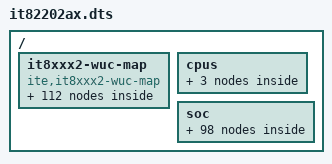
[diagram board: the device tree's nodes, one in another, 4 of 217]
/dts-v1/;

/ {
	#address-cells = < 0x1 >;
	#size-cells = < 0x1 >;
	it8xxx2-wuc-map {
		compatible = "ite,it8xxx2-wuc-map";
		wuc_wu20: wu20 {
			wucs = < &wuc2 0x1 >;
		};
		wuc_wu21: wu21 {
			wucs = < &wuc2 0x2 >;
		};
		wuc_wu22: wu22 {
			wucs = < &wuc2 0x4 >;
		};
		wuc_wu23: wu23 {
			wucs = < &wuc2 0x8 >;
		};
		wuc_wu24: wu24 {
			wucs = < &wuc2 0x10 >;
		};
		wuc_wu25: wu25 {
			wucs = < &wuc2 0x20 >;
		};
		wuc_wu30: wu30 {
			wucs = < &wuc3 0x1 >;
			phandle = < 0x18 >;
		};
		wuc_wu31: wu31 {
			wucs = < &wuc3 0x2 >;
			phandle = < 0x19 >;
		};
		wuc_wu32: wu32 {
			wucs = < &wuc3 0x4 >;
			phandle = < 0x1a >;
		};
		wuc_wu33: wu33 {
			wucs = < &wuc3 0x8 >;
			phandle = < 0x1b >;
		};
		wuc_wu34: wu34 {
			wucs = < &wuc3 0x10 >;
			phandle = < 0x1c >;
		};
		wuc_wu35: wu35 {
			wucs = < &wuc3 0x20 >;
			phandle = < 0x1d >;
		};
		wuc_wu36: wu36 {
			wucs = < &wuc3 0x40 >;
			phandle = < 0x1e >;
		};
		wuc_wu37: wu37 {
			wucs = < &wuc3 0x80 >;
			phandle = < 0x1f >;
		};
		wuc_wu40: wu40 {
			wucs = < &wuc4 0x1 >;
		};
		wuc_wu42: wu42 {
			wucs = < &wuc4 0x4 >;
			phandle = < 0x16 >;
		};
		wuc_wu45: wu45 {
			wucs = < &wuc4 0x20 >;
		};
		wuc_wu46: wu46 {
			wucs = < &wuc4 0x40 >;
		};
		wuc_wu50: wu50 {
			wucs = < &wuc5 0x1 >;
		};
		wuc_wu51: wu51 {
			wucs = < &wuc5 0x2 >;
		};
		wuc_wu52: wu52 {
			wucs = < &wuc5 0x4 >;
		};
		wuc_wu53: wu53 {
			wucs = < &wuc5 0x8 >;
		};
		wuc_wu54: wu54 {
			wucs = < &wuc5 0x10 >;
		};
		wuc_wu55: wu55 {
			wucs = < &wuc5 0x20 >;
		};
		wuc_wu56: wu56 {
			wucs = < &wuc5 0x40 >;
		};
		wuc_wu57: wu57 {
			wucs = < &wuc5 0x80 >;
		};
		wuc_wu60: wu60 {
			wucs = < &wuc6 0x1 >;
		};
		wuc_wu61: wu61 {
			wucs = < &wuc6 0x2 >;
		};
		wuc_wu62: wu62 {
			wucs = < &wuc6 0x4 >;
		};
		wuc_wu63: wu63 {
			wucs = < &wuc6 0x8 >;
		};
		wuc_wu64: wu64 {
			wucs = < &wuc6 0x10 >;
		};
		wuc_wu65: wu65 {
			wucs = < &wuc6 0x20 >;
		};
		wuc_wu66: wu66 {
			wucs = < &wuc6 0x40 >;
		};
		wuc_wu67: wu67 {
			wucs = < &wuc6 0x80 >;
		};
		wuc_wu70: wu70 {
			wucs = < &wuc7 0x1 >;
		};
		wuc_wu71: wu71 {
			wucs = < &wuc7 0x2 >;
		};
		wuc_wu72: wu72 {
			wucs = < &wuc7 0x4 >;
		};
		wuc_wu73: wu73 {
			wucs = < &wuc7 0x8 >;
		};
		wuc_wu74: wu74 {
			wucs = < &wuc7 0x10 >;
		};
		wuc_wu75: wu75 {
			wucs = < &wuc7 0x20 >;
		};
		wuc_wu76: wu76 {
			wucs = < &wuc7 0x40 >;
		};
		wuc_wu77: wu77 {
			wucs = < &wuc7 0x80 >;
		};
		wuc_wu80: wu80 {
			wucs = < &wuc8 0x1 >;
		};
		wuc_wu81: wu81 {
			wucs = < &wuc8 0x2 >;
		};
		wuc_wu82: wu82 {
			wucs = < &wuc8 0x4 >;
		};
		wuc_wu83: wu83 {
			wucs = < &wuc8 0x8 >;
		};
		wuc_wu84: wu84 {
			wucs = < &wuc8 0x10 >;
		};
		wuc_wu85: wu85 {
			wucs = < &wuc8 0x20 >;
		};
		wuc_wu86: wu86 {
			wucs = < &wuc8 0x40 >;
		};
		wuc_wu87: wu87 {
			wucs = < &wuc8 0x80 >;
		};
		wuc_wu88: wu88 {
			wucs = < &wuc9 0x1 >;
		};
		wuc_wu89: wu89 {
			wucs = < &wuc9 0x2 >;
		};
		wuc_wu90: wu90 {
			wucs = < &wuc9 0x4 >;
			phandle = < 0x24 >;
		};
		wuc_wu91: wu91 {
			wucs = < &wuc9 0x8 >;
		};
		wuc_wu92: wu92 {
			wucs = < &wuc9 0x10 >;
		};
		wuc_wu93: wu93 {
			wucs = < &wuc9 0x20 >;
		};
		wuc_wu94: wu94 {
			wucs = < &wuc9 0x40 >;
		};
		wuc_wu95: wu95 {
			wucs = < &wuc9 0x80 >;
		};
		wuc_wu96: wu96 {
			wucs = < &wuc10 0x1 >;
		};
		wuc_wu97: wu97 {
			wucs = < &wuc10 0x2 >;
		};
		wuc_wu98: wu98 {
			wucs = < &wuc10 0x4 >;
		};
		wuc_wu99: wu99 {
			wucs = < &wuc10 0x8 >;
		};
		wuc_wu100: wu100 {
			wucs = < &wuc10 0x10 >;
		};
		wuc_wu101: wu101 {
			wucs = < &wuc10 0x20 >;
		};
		wuc_wu102: wu102 {
			wucs = < &wuc10 0x40 >;
		};
		wuc_wu103: wu103 {
			wucs = < &wuc10 0x80 >;
		};
		wuc_wu104: wu104 {
			wucs = < &wuc11 0x1 >;
		};
		wuc_wu105: wu105 {
			wucs = < &wuc11 0x2 >;
		};
		wuc_wu106: wu106 {
			wucs = < &wuc11 0x4 >;
		};
		wuc_wu107: wu107 {
			wucs = < &wuc11 0x8 >;
		};
		wuc_wu108: wu108 {
			wucs = < &wuc11 0x10 >;
		};
		wuc_wu109: wu109 {
			wucs = < &wuc11 0x20 >;
		};
		wuc_wu110: wu110 {
			wucs = < &wuc11 0x40 >;
		};
		wuc_wu111: wu111 {
			wucs = < &wuc11 0x80 >;
		};
		wuc_wu112: wu112 {
			wucs = < &wuc12 0x1 >;
		};
		wuc_wu113: wu113 {
			wucs = < &wuc12 0x2 >;
		};
		wuc_wu114: wu114 {
			wucs = < &wuc12 0x4 >;
		};
		wuc_wu115: wu115 {
			wucs = < &wuc12 0x8 >;
		};
		wuc_wu116: wu116 {
			wucs = < &wuc12 0x10 >;
		};
		wuc_wu117: wu117 {
			wucs = < &wuc12 0x20 >;
		};
		wuc_wu118: wu118 {
			wucs = < &wuc12 0x40 >;
		};
		wuc_wu119: wu119 {
			wucs = < &wuc12 0x80 >;
		};
		wuc_wu120: wu120 {
			wucs = < &wuc13 0x1 >;
		};
		wuc_wu121: wu121 {
			wucs = < &wuc13 0x2 >;
		};
		wuc_wu122: wu122 {
			wucs = < &wuc13 0x4 >;
		};
		wuc_wu123: wu123 {
			wucs = < &wuc13 0x8 >;
		};
		wuc_wu124: wu124 {
			wucs = < &wuc13 0x10 >;
		};
		wuc_wu125: wu125 {
			wucs = < &wuc13 0x20 >;
		};
		wuc_wu126: wu126 {
			wucs = < &wuc13 0x40 >;
		};
		wuc_wu128: wu128 {
			wucs = < &wuc14 0x1 >;
		};
		wuc_wu129: wu129 {
			wucs = < &wuc14 0x2 >;
		};
		wuc_wu130: wu130 {
			wucs = < &wuc14 0x4 >;
		};
		wuc_wu131: wu131 {
			wucs = < &wuc14 0x8 >;
		};
		wuc_wu132: wu132 {
			wucs = < &wuc14 0x10 >;
		};
		wuc_wu133: wu133 {
			wucs = < &wuc14 0x20 >;
		};
		wuc_wu134: wu134 {
			wucs = < &wuc14 0x40 >;
		};
		wuc_wu135: wu135 {
			wucs = < &wuc14 0x80 >;
		};
		wuc_wu136: wu136 {
			wucs = < &wuc15 0x1 >;
		};
		wuc_wu137: wu137 {
			wucs = < &wuc15 0x2 >;
		};
		wuc_wu138: wu138 {
			wucs = < &wuc15 0x4 >;
		};
		wuc_wu139: wu139 {
			wucs = < &wuc15 0x8 >;
		};
		wuc_wu140: wu140 {
			wucs = < &wuc15 0x10 >;
		};
		wuc_wu141: wu141 {
			wucs = < &wuc15 0x20 >;
		};
		wuc_wu142: wu142 {
			wucs = < &wuc15 0x40 >;
		};
		wuc_wu143: wu143 {
			wucs = < &wuc15 0x80 >;
		};
		wuc_wu144: wu144 {
			wucs = < &wuc16 0x1 >;
		};
		wuc_wu145: wu145 {
			wucs = < &wuc16 0x2 >;
		};
		wuc_wu146: wu146 {
			wucs = < &wuc16 0x4 >;
		};
		wuc_wu147: wu147 {
			wucs = < &wuc16 0x8 >;
		};
		wuc_wu148: wu148 {
			wucs = < &wuc16 0x10 >;
		};
		wuc_wu149: wu149 {
			wucs = < &wuc16 0x20 >;
		};
		wuc_wu150: wu150 {
			wucs = < &wuc16 0x40 >;
		};
	};
	cpus {
		#address-cells = < 0x1 >;
		#size-cells = < 0x0 >;
		cpu0: cpu@0 {
			compatible = "ite,riscv-ite", "riscv";
			riscv,isa = "rv32imafc_zifencei";
			device_type = "cpu";
			reg = < 0x0 >;
			cpu-power-states = < &standby >;
		};
		power-states {
			standby: standby {
				compatible = "zephyr,power-state";
				power-state-name = "standby";
				min-residency-us = < 0x1f4 >;
				phandle = < 0x10 >;
			};
		};
	};
	soc {
		#address-cells = < 0x1 >;
		#size-cells = < 0x1 >;
		ranges;
		bbram: bb-ram@f02200 {
			#address-cells = < 0x1 >;
			#size-cells = < 0x1 >;
			compatible = "ite,it8xxx2-bbram";
			status = "okay";
			reg = < 0xf02200 0xc0 >;
		};
		flashctrl: flash-controller@f01000 {
			compatible = "ite,it8xxx2-flash-controller";
			reg = < 0xf01000 0x100 >;
			#address-cells = < 0x1 >;
			#size-cells = < 0x1 >;
			flash0: flash@80000000 {
				compatible = "soc-nv-flash";
				reg = < 0x80000000 0x100000 >;
				erase-block-size = < 0x1000 >;
				write-block-size = < 0x4 >;
			};
		};
		sram0: memory@80100000 {
			compatible = "mmio-sram";
			reg = < 0x80100000 0x40000 >;
		};
		ilm: ilm@f01040 {
			compatible = "ite,it8xxx2-ilm";
			reg = < 0xf01040 0x3 0xf01043 0x3 0xf01046 0x3 0xf01049 0x3 0xf0104c 0x3 0xf01081 0x3 0xf01084 0x3 0xf01087 0x3 0xf0108a 0x3 0xf0108d 0x3 0xf01090 0x3 0xf01093 0x3 0xf01096 0x3 0xf010b0 0x3 0xf010b3 0x3 0xf010b6 0x3 0xf010b9 0x3 0xf010bc 0x3 0xf010bf 0x3 0xf010c2 0x3 0xf010c5 0x3 0xf010c8 0x3 0xf010cb 0x3 0xf010ce 0x3 >;
		};
		uart1: uart@f02700 {
			compatible = "ns16550";
			reg = < 0xf02700 0x20 >;
			status = "disabled";
			current-speed = < 0x1c200 >;
			clock-frequency = < 0x1c2000 >;
			interrupts = < 0x26 0x1 >;
			interrupt-parent = < &intc >;
			reg-shift = < 0x0 >;
			phandle = < 0x13 >;
		};
		uart2: uart@f02800 {
			compatible = "ns16550";
			reg = < 0xf02800 0x20 >;
			status = "disabled";
			current-speed = < 0x70800 >;
			clock-frequency = < 0x1c2000 >;
			interrupts = < 0x27 0x1 >;
			interrupt-parent = < &intc >;
			reg-shift = < 0x0 >;
			phandle = < 0x15 >;
		};
		ite_uart1_wrapper: uartwrapper@f02720 {
			compatible = "ite,it8xxx2-uart";
			reg = < 0xf02720 0x20 >;
			status = "disabled";
			port-num = < 0x1 >;
			gpios = < &gpiob 0x0 0x0 >;
			uart-dev = < &uart1 >;
		};
		ite_uart2_wrapper: uartwrapper@f02820 {
			compatible = "ite,it8xxx2-uart";
			reg = < 0xf02820 0x20 >;
			status = "disabled";
			port-num = < 0x2 >;
			gpios = < &gpiof 0x0 0x0 >;
			uart-dev = < &uart2 >;
		};
		timer: timer@f01f10 {
			compatible = "ite,it8xxx2-timer";
			reg = < 0xf01f10 0x52 >;
			interrupts = < 0x9b 0x1 0x9c 0x1 0x9d 0x1 0x9e 0x1 0x9f 0x1 0x50 0x1 >;
			interrupt-parent = < &intc >;
		};
		gpioa: gpio@f01601 {
			compatible = "ite,it8xxx2-gpio-v2";
			reg = < 0xf01601 0x1 0xf01618 0x1 0xf01630 0x1 0xf01648 0x1 0xf01660 0x8 >;
			ngpios = < 0x8 >;
			gpio-controller;
			interrupts = < 0x60 0x4 0x61 0x4 0x62 0x4 0x58 0x4 0x59 0x4 0x5a 0x4 0x5b 0x4 0x69 0x4 >;
			interrupt-parent = < &intc >;
			#gpio-cells = < 0x2 >;
			wuc-base = < 0xf01b20 0xf01b20 0xf01b20 0xf01b1c 0xf01b1c 0xf01b1c 0xf01b1c 0xf01b24 >;
			wuc-mask = < 0x8 0x10 0x20 0x1 0x2 0x4 0x8 0x10 >;
			has-volt-sel = < 0x1 0x1 0x1 0x1 0x1 0x1 0x1 0x1 >;
			phandle = < 0x23 >;
		};
		gpiob: gpio@f01602 {
			compatible = "ite,it8xxx2-gpio-v2";
			reg = < 0xf01602 0x1 0xf01619 0x1 0xf01631 0x1 0xf01649 0x1 0xf01668 0x8 >;
			ngpios = < 0x7 >;
			gpio-controller;
			interrupts = < 0x6a 0x4 0x6b 0x4 0x5c 0x4 0x6c 0x4 0x63 0x4 0x6d 0x4 0x6e 0x4 0x0 0x0 >;
			interrupt-parent = < &intc >;
			wakeup-source;
			#gpio-cells = < 0x2 >;
			wuc-base = < 0xf01b24 0xf01b24 0xf01b1c 0xf01b24 0xf01b20 0xf01b28 0xf01b28 0x0 >;
			wuc-mask = < 0x20 0x40 0x10 0x80 0x40 0x1 0x2 0x0 >;
			has-volt-sel = < 0x1 0x1 0x1 0x1 0x1 0x1 0x1 0x0 >;
			phandle = < 0x12 >;
		};
		gpioc: gpio@f01603 {
			compatible = "ite,it8xxx2-gpio-v2";
			reg = < 0xf01603 0x1 0xf0161a 0x1 0xf01632 0x1 0xf0164a 0x1 0xf01670 0x8 >;
			ngpios = < 0x8 >;
			gpio-controller;
			interrupts = < 0x5d 0x4 0x70 0x4 0x64 0x4 0x71 0x4 0x15 0x4 0x72 0x4 0x6 0x4 0x5e 0x4 >;
			interrupt-parent = < &intc >;
			#gpio-cells = < 0x2 >;
			wuc-base = < 0xf01b1c 0xf01b28 0xf01b20 0xf01b28 0xf01b04 0xf01b28 0xf01b04 0xf01b1c >;
			wuc-mask = < 0x20 0x8 0x80 0x10 0x4 0x20 0x8 0x40 >;
			has-volt-sel = < 0x1 0x1 0x1 0x1 0x1 0x1 0x1 0x1 >;
			phandle = < 0x20 >;
		};
		gpiod: gpio@f01604 {
			compatible = "ite,it8xxx2-gpio-v2";
			reg = < 0xf01604 0x1 0xf0161b 0x1 0xf01633 0x1 0xf0164b 0x1 0xf01678 0x8 >;
			ngpios = < 0x8 >;
			gpio-controller;
			interrupts = < 0x1 0x4 0x1f 0x4 0x11 0x4 0x73 0x4 0x74 0x4 0x75 0x4 0x76 0x4 0x5f 0x4 >;
			interrupt-parent = < &intc >;
			#gpio-cells = < 0x2 >;
			wuc-base = < 0xf01b04 0xf01b04 0xf01b04 0xf01b28 0xf01b28 0xf01b2c 0xf01b2c 0xf01b1c >;
			wuc-mask = < 0x1 0x2 0x10 0x40 0x80 0x1 0x2 0x80 >;
			has-volt-sel = < 0x1 0x1 0x1 0x1 0x1 0x1 0x1 0x1 >;
		};
		gpioe: gpio@f01605 {
			compatible = "ite,it8xxx2-gpio-v2";
			reg = < 0xf01605 0x1 0xf0161c 0x1 0xf01634 0x1 0xf0164c 0x1 0xf01680 0x8 >;
			ngpios = < 0x8 >;
			gpio-controller;
			interrupts = < 0x48 0x4 0x49 0x4 0x4a 0x4 0x4b 0x4 0x77 0x4 0xb0 0x4 0xb1 0x4 0xb2 0x4 >;
			interrupt-parent = < &intc >;
			#gpio-cells = < 0x2 >;
			wuc-base = < 0xf01b18 0xf01b18 0xf01b18 0xf01b18 0xf01b2c 0xf01b0c 0xf01b0c 0xf01b0c >;
			wuc-mask = < 0x1 0x2 0x4 0x8 0x4 0x1 0x20 0x40 >;
			has-volt-sel = < 0x1 0x1 0x1 0x1 0x1 0x1 0x1 0x1 >;
			phandle = < 0x22 >;
		};
		gpiof: gpio@f01606 {
			compatible = "ite,it8xxx2-gpio-v2";
			reg = < 0xf01606 0x1 0xf0161d 0x1 0xf01635 0x1 0xf0164d 0x1 0xf01688 0x8 >;
			ngpios = < 0x8 >;
			gpio-controller;
			interrupts = < 0x65 0x4 0x66 0x4 0x67 0x4 0x68 0x4 0x34 0x4 0x35 0x4 0x36 0x4 0x37 0x4 >;
			interrupt-parent = < &intc >;
			#gpio-cells = < 0x2 >;
			wuc-base = < 0xf01b24 0xf01b24 0xf01b24 0xf01b24 0xf01b14 0xf01b14 0xf01b14 0xf01b14 >;
			wuc-mask = < 0x1 0x2 0x4 0x8 0x10 0x20 0x40 0x80 >;
			has-volt-sel = < 0x1 0x1 0x1 0x1 0x1 0x1 0x1 0x1 >;
			phandle = < 0x14 >;
		};
		gpiog: gpio@f01607 {
			compatible = "ite,it8xxx2-gpio-v2";
			reg = < 0xf01607 0x1 0xf0161e 0x1 0xf01636 0x1 0xf0164e 0x1 0xf01690 0x8 >;
			ngpios = < 0x8 >;
			gpio-controller;
			interrupts = < 0x78 0x4 0x79 0x4 0x7a 0x4 0x90 0x4 0x91 0x4 0x92 0x4 0x7b 0x4 0x93 0x4 >;
			interrupt-parent = < &intc >;
			#gpio-cells = < 0x2 >;
			wuc-base = < 0xf01b2c 0xf01b2c 0xf01b2c 0xf01b30 0xf01b30 0xf01b30 0xf01b2c 0xf01b30 >;
			wuc-mask = < 0x8 0x10 0x20 0x8 0x10 0x20 0x40 0x40 >;
			has-volt-sel = < 0x1 0x1 0x1 0x0 0x0 0x0 0x1 0x0 >;
		};
		gpioh: gpio@f01608 {
			compatible = "ite,it8xxx2-gpio-v2";
			reg = < 0xf01608 0x1 0xf0161f 0x1 0xf01637 0x1 0xf0164f 0x1 0xf01698 0x8 >;
			ngpios = < 0x7 >;
			gpio-controller;
			interrupts = < 0x30 0x4 0x31 0x4 0x32 0x4 0x33 0x4 0x55 0x4 0x56 0x4 0x57 0x4 0x0 0x0 >;
			interrupt-parent = < &intc >;
			wakeup-source;
			#gpio-cells = < 0x2 >;
			wuc-base = < 0xf01b14 0xf01b14 0xf01b14 0xf01b14 0xf01b20 0xf01b20 0xf01b20 0x0 >;
			wuc-mask = < 0x1 0x2 0x4 0x8 0x1 0x2 0x4 0x0 >;
			has-volt-sel = < 0x1 0x1 0x1 0x1 0x1 0x1 0x1 0x0 >;
			phandle = < 0x21 >;
		};
		gpioi: gpio@f01609 {
			compatible = "ite,it8xxx2-gpio-v2";
			reg = < 0xf01609 0x1 0xf01620 0x1 0xf01638 0x1 0xf01650 0x1 0xf016a0 0x8 >;
			ngpios = < 0x8 >;
			gpio-controller;
			interrupts = < 0x7c 0x4 0x7d 0x4 0x7e 0x4 0x7f 0x4 0x4c 0x4 0x4d 0x4 0x4e 0x4 0x4f 0x4 >;
			interrupt-parent = < &intc >;
			#gpio-cells = < 0x2 >;
			wuc-base = < 0xf01b2c 0xf01b30 0xf01b30 0xf01b30 0xf01b18 0xf01b18 0xf01b18 0xf01b18 >;
			wuc-mask = < 0x80 0x1 0x2 0x4 0x10 0x20 0x40 0x80 >;
			has-volt-sel = < 0x1 0x1 0x1 0x1 0x1 0x1 0x1 0x1 >;
		};
		gpioj: gpio@f0160a {
			compatible = "ite,it8xxx2-gpio-v2";
			reg = < 0xf0160a 0x1 0xf01621 0x1 0xf01639 0x1 0xf01651 0x1 0xf016a8 0x8 >;
			ngpios = < 0x8 >;
			gpio-controller;
			interrupts = < 0x80 0x4 0x81 0x4 0x82 0x4 0x83 0x4 0x84 0x4 0x85 0x4 0x86 0x4 0x87 0x4 >;
			interrupt-parent = < &intc >;
			#gpio-cells = < 0x2 >;
			wuc-base = < 0xf01b34 0xf01b34 0xf01b34 0xf01b34 0xf01b34 0xf01b34 0xf01b34 0xf01b34 >;
			wuc-mask = < 0x1 0x2 0x4 0x8 0x10 0x20 0x40 0x80 >;
			has-volt-sel = < 0x1 0x1 0x1 0x1 0x1 0x1 0x1 0x1 >;
		};
		gpiok: gpio@f0160b {
			compatible = "ite,it8xxx2-gpio-v2";
			reg = < 0xf0160b 0x1 0xf01622 0x1 0xf0163a 0x1 0xf01652 0x1 0xf016b0 0x8 >;
			ngpios = < 0x8 >;
			gpio-controller;
			interrupts = < 0x28 0x4 0x29 0x4 0x2a 0x4 0x2b 0x4 0x2c 0x4 0x2d 0x4 0x2e 0x4 0x2f 0x4 >;
			interrupt-parent = < &intc >;
			#gpio-cells = < 0x2 >;
			wuc-base = < 0xf01b10 0xf01b10 0xf01b10 0xf01b10 0xf01b10 0xf01b10 0xf01b10 0xf01b10 >;
			wuc-mask = < 0x1 0x2 0x4 0x8 0x10 0x20 0x40 0x80 >;
			has-volt-sel = < 0x1 0x1 0x1 0x1 0x1 0x1 0x1 0x1 >;
		};
		gpiol: gpio@f0160c {
			compatible = "ite,it8xxx2-gpio-v2";
			reg = < 0xf0160c 0x1 0xf01623 0x1 0xf0163b 0x1 0xf01653 0x1 0xf016b8 0x8 >;
			ngpios = < 0x8 >;
			gpio-controller;
			interrupts = < 0x88 0x4 0x89 0x4 0x8a 0x4 0x8b 0x4 0x8c 0x4 0x8d 0x4 0x8e 0x4 0x8f 0x4 >;
			interrupt-parent = < &intc >;
			#gpio-cells = < 0x2 >;
			wuc-base = < 0xf01b38 0xf01b38 0xf01b38 0xf01b38 0xf01b38 0xf01b38 0xf01b38 0xf01b38 >;
			wuc-mask = < 0x1 0x2 0x4 0x8 0x10 0x20 0x40 0x80 >;
			has-volt-sel = < 0x1 0x1 0x1 0x1 0x1 0x1 0x1 0x1 >;
		};
		gpiom: gpio@f0160d {
			compatible = "ite,it8xxx2-gpio-v2";
			reg = < 0xf0160d 0x1 0xf01624 0x1 0xf0163c 0x1 0xf01654 0x1 0xf016c0 0x8 >;
			ngpios = < 0x7 >;
			gpio-controller;
			interrupts = < 0xb3 0x4 0xb4 0x4 0xb5 0x4 0xb6 0x4 0xb7 0x4 0xb8 0x4 0xb9 0x4 0x0 0x0 >;
			interrupt-parent = < &intc >;
			#gpio-cells = < 0x2 >;
			wuc-base = < 0xf01b3c 0xf01b3c 0xf01b3c 0xf01b3c 0xf01b3c 0xf01b3c 0xf01b3c 0x0 >;
			wuc-mask = < 0x1 0x2 0x4 0x8 0x10 0x20 0x40 0x0 >;
			has-volt-sel = < 0x1 0x1 0x1 0x1 0x1 0x1 0x1 0x0 >;
		};
		espi0: espi@f03100 {
			compatible = "ite,it8xxx2-espi";
			reg = < 0xf03100 0xd8 0xf03200 0x9a 0xf03300 0xd0 0xf03400 0xc0 0xf01200 0x6 0xf01300 0xb 0xf01500 0x100 0xf01000 0xd1 >;
			interrupts = < 0xa2 0x4 0xa3 0x4 0x18 0x4 0x2 0x4 0x19 0x4 0xa4 0x4 0x1b 0x4 0x5 0x4 >;
			interrupt-parent = < &intc >;
			wucctrl = < &wuc_wu42 >;
			#address-cells = < 0x1 >;
			#size-cells = < 0x1 >;
			status = "disabled";
		};
		spi0: spi@f02600 {
			#address-cells = < 0x1 >;
			#size-cells = < 0x0 >;
			compatible = "ite,it8xxx2-sspi";
			reg = < 0xf02600 0x40 >;
			interrupt-parent = < &intc >;
			interrupts = < 0x25 0x1 >;
			clock-frequency = < 0x1c200 >;
		};
		spi1: spi@f02640 {
			#address-cells = < 0x1 >;
			#size-cells = < 0x0 >;
			compatible = "ite,it8xxx2-sspi";
			reg = < 0xf02640 0x40 >;
			interrupts = < 0x25 0x1 >;
			interrupt-parent = < &intc >;
			status = "okay";
		};
		shi0: shi@f03a00 {
			compatible = "ite,it8xxx2-shi";
			reg = < 0xf03a00 0x30 >;
			interrupts = < 0xab 0x0 >;
			interrupt-parent = < &intc >;
			status = "disabled";
			buffer-rx-size = < 0x100 >;
			buffer-tx-size = < 0x100 >;
		};
		adc0: adc@f01900 {
			compatible = "ite,it8xxx2-adc";
			reg = < 0xf01900 0x45 >;
			interrupts = < 0x8 0x0 >;
			interrupt-parent = < &intc >;
			status = "disabled";
			#io-channel-cells = < 0x1 >;
		};
		vcmp0: vcmp@f01946 {
			compatible = "ite,it8xxx2-vcmp";
			reg = < 0xf01946 0x1 0xf01977 0x1 0xf01937 0x1 0xf01947 0x1 0xf01948 0x1 0xf01945 0x1 0xf0196d 0x1 >;
			interrupts = < 0x97 0x4 >;
			interrupt-parent = < &intc >;
			vcmp-ch = < 0x0 >;
			status = "disabled";
		};
		vcmp1: vcmp@f01949 {
			compatible = "ite,it8xxx2-vcmp";
			reg = < 0xf01949 0x1 0xf01978 0x1 0xf01937 0x1 0xf0194a 0x1 0xf0194b 0x1 0xf01945 0x1 0xf0196d 0x1 >;
			interrupts = < 0x97 0x4 >;
			interrupt-parent = < &intc >;
			vcmp-ch = < 0x1 >;
			status = "disabled";
		};
		vcmp2: vcmp@f0194c {
			compatible = "ite,it8xxx2-vcmp";
			reg = < 0xf0194c 0x1 0xf01979 0x1 0xf01937 0x1 0xf0194d 0x1 0xf0194e 0x1 0xf01945 0x1 0xf0196d 0x1 >;
			interrupts = < 0x97 0x4 >;
			interrupt-parent = < &intc >;
			vcmp-ch = < 0x2 >;
			status = "disabled";
		};
		vcmp3: vcmp@f0196e {
			compatible = "ite,it8xxx2-vcmp";
			reg = < 0xf0196e 0x1 0xf0197a 0x1 0xf01937 0x1 0xf0196f 0x1 0xf01970 0x1 0xf01945 0x1 0xf0196d 0x1 >;
			interrupts = < 0x97 0x4 >;
			interrupt-parent = < &intc >;
			vcmp-ch = < 0x3 >;
			status = "disabled";
		};
		vcmp4: vcmp@f01971 {
			compatible = "ite,it8xxx2-vcmp";
			reg = < 0xf01971 0x1 0xf0197b 0x1 0xf01937 0x1 0xf01972 0x1 0xf01973 0x1 0xf01945 0x1 0xf0196d 0x1 >;
			interrupts = < 0x97 0x4 >;
			interrupt-parent = < &intc >;
			vcmp-ch = < 0x4 >;
			status = "disabled";
		};
		vcmp5: vcmp@f01974 {
			compatible = "ite,it8xxx2-vcmp";
			reg = < 0xf01974 0x1 0xf0197c 0x1 0xf01937 0x1 0xf01975 0x1 0xf01976 0x1 0xf01945 0x1 0xf0196d 0x1 >;
			interrupts = < 0x97 0x4 >;
			interrupt-parent = < &intc >;
			vcmp-ch = < 0x5 >;
			status = "disabled";
		};
		ecpm: clock-controller@f01e00 {
			compatible = "ite,it8xxx2-ecpm";
			reg = < 0xf01e00 0x11 >;
			reg-names = "ecpm";
		};
		prs: pwmprs@f01800 {
			compatible = "ite,it8xxx2-pwmprs";
			reg = < 0xf01800 0x1 >;
			phandle = < 0x17 >;
		};
		pwm0: pwm@f01802 {
			compatible = "ite,it8xxx2-pwm";
			reg = < 0xf01802 0x1 0xf0180c 0x1 0xf0180f 0x1 0xf0180a 0x1 >;
			channel = < 0x0 >;
			status = "disabled";
			pwmctrl = < &prs >;
			#pwm-cells = < 0x3 >;
		};
		pwm1: pwm@f01803 {
			compatible = "ite,it8xxx2-pwm";
			reg = < 0xf01803 0x1 0xf0180c 0x1 0xf0180f 0x1 0xf0180a 0x1 >;
			channel = < 0x1 >;
			status = "disabled";
			pwmctrl = < &prs >;
			#pwm-cells = < 0x3 >;
		};
		pwm2: pwm@f01804 {
			compatible = "ite,it8xxx2-pwm";
			reg = < 0xf01804 0x1 0xf0180c 0x1 0xf0180f 0x1 0xf0180a 0x1 >;
			channel = < 0x2 >;
			status = "disabled";
			pwmctrl = < &prs >;
			#pwm-cells = < 0x3 >;
		};
		pwm3: pwm@f01805 {
			compatible = "ite,it8xxx2-pwm";
			reg = < 0xf01805 0x1 0xf0180c 0x1 0xf0180f 0x1 0xf0180a 0x1 >;
			channel = < 0x3 >;
			status = "disabled";
			pwmctrl = < &prs >;
			#pwm-cells = < 0x3 >;
		};
		pwm4: pwm@f01806 {
			compatible = "ite,it8xxx2-pwm";
			reg = < 0xf01806 0x1 0xf0180d 0x1 0xf0180f 0x1 0xf0180a 0x1 >;
			channel = < 0x4 >;
			status = "disabled";
			pwmctrl = < &prs >;
			#pwm-cells = < 0x3 >;
		};
		pwm5: pwm@f01807 {
			compatible = "ite,it8xxx2-pwm";
			reg = < 0xf01807 0x1 0xf0180d 0x1 0xf0180f 0x1 0xf0180a 0x1 >;
			channel = < 0x5 >;
			status = "disabled";
			pwmctrl = < &prs >;
			#pwm-cells = < 0x3 >;
		};
		pwm6: pwm@f01808 {
			compatible = "ite,it8xxx2-pwm";
			reg = < 0xf01808 0x1 0xf0180d 0x1 0xf0180f 0x1 0xf0180a 0x1 >;
			channel = < 0x6 >;
			status = "disabled";
			pwmctrl = < &prs >;
			#pwm-cells = < 0x3 >;
		};
		pwm7: pwm@f01809 {
			compatible = "ite,it8xxx2-pwm";
			reg = < 0xf01809 0x1 0xf0180d 0x1 0xf0180f 0x1 0xf0180a 0x1 >;
			channel = < 0x7 >;
			status = "disabled";
			pwmctrl = < &prs >;
			#pwm-cells = < 0x3 >;
		};
		tach0: tach@f0181e {
			compatible = "ite,it8xxx2-tach";
			reg = < 0xf0181e 0x1 0xf0181f 0x1 0xf01848 0x1 >;
			dvs-bit = < 0x8 >;
			chsel-bit = < 0x4 >;
			status = "disabled";
		};
		tach1: tach@f01820 {
			compatible = "ite,it8xxx2-tach";
			reg = < 0xf01820 0x1 0xf01821 0x1 0xf01848 0x1 >;
			dvs-bit = < 0x2 >;
			chsel-bit = < 0x1 >;
			status = "disabled";
		};
		gctrl: general-control@f02000 {
			compatible = "ite,it8xxx2-gctrl";
			reg = < 0xf02000 0x100 >;
		};
		peci0: peci@f02c00 {
			compatible = "ite,it8xxx2-peci";
			reg = < 0xf02c00 0xf >;
			#address-cells = < 0x1 >;
			#size-cells = < 0x0 >;
			interrupt-parent = < &intc >;
			interrupts = < 0xa0 0x4 >;
			status = "disabled";
		};
		kbd: kbd@f01d00 {
			compatible = "ite,it8xxx2-kbd";
			reg = < 0xf01d00 0x29 >;
			interrupt-parent = < &intc >;
			interrupts = < 0xd 0x4 >;
			status = "disabled";
			wucctrl = < &wuc_wu30 &wuc_wu31 &wuc_wu32 &wuc_wu33 &wuc_wu34 &wuc_wu35 &wuc_wu36 &wuc_wu37 >;
			kso16-gpios = < &gpioc 0x3 0x16 >;
			kso17-gpios = < &gpioc 0x5 0x16 >;
		};
		usbpd0: usbpd@f03700 {
			compatible = "ite,it8xxx2-usbpd";
			reg = < 0xf03700 0x100 >;
			status = "disabled";
		};
		usbpd1: usbpd@f03800 {
			compatible = "ite,it8xxx2-usbpd";
			reg = < 0xf03800 0x100 >;
			status = "disabled";
		};
		intc: interrupt-controller@f03f00 {
			compatible = "ite,it8xxx2-intc-v2";
			#address-cells = < 0x0 >;
			#interrupt-cells = < 0x2 >;
			interrupt-controller;
			reg = < 0xf03f00 0x100 >;
			phandle = < 0x11 >;
		};
		twd0: watchdog@f01f80 {
			compatible = "ite,it8xxx2-watchdog";
			reg = < 0xf01f80 0xf >;
			interrupts = < 0x1e 0x1 0x3a 0x1 >;
			interrupt-parent = < &intc >;
		};
		gpiogcr: gpio-gcr@f03e00 {
			compatible = "ite,it8xxx2-gpiogcr";
			reg = < 0xf03e00 0x2f >;
		};
		gpioksi: gpio@f01d08 {
			compatible = "ite,it8xxx2-gpio-v2";
			reg = < 0xf01d08 0x1 0xf01d09 0x1 0xf01d2c 0x1 0x0 0x1 0xf01d40 0x8 >;
			ngpios = < 0x8 >;
			gpio-controller;
			interrupts = < 0x0 0x0 0x0 0x0 0x0 0x0 0x0 0x0 0x0 0x0 0x0 0x0 0x0 0x0 0x0 0x0 >;
			interrupt-parent = < &intc >;
			keyboard-controller;
			#gpio-cells = < 0x2 >;
		};
		gpioksoh: gpio@f01d01 {
			compatible = "ite,it8xxx2-gpio-v2";
			reg = < 0xf01d01 0x1 0xf01d0c 0x1 0xf01d2d 0x1 0x0 0x1 0xf01d50 0x8 >;
			ngpios = < 0x8 >;
			gpio-controller;
			interrupts = < 0x0 0x0 0x0 0x0 0x0 0x0 0x0 0x0 0x0 0x0 0x0 0x0 0x0 0x0 0x0 0x0 >;
			interrupt-parent = < &intc >;
			keyboard-controller;
			#gpio-cells = < 0x2 >;
		};
		gpioksol: gpio@f01d00 {
			compatible = "ite,it8xxx2-gpio-v2";
			reg = < 0xf01d00 0x1 0xf01d0f 0x1 0xf01d2e 0x1 0x0 0x1 0xf01d48 0x8 >;
			ngpios = < 0x8 >;
			gpio-controller;
			interrupts = < 0x0 0x0 0x0 0x0 0x0 0x0 0x0 0x0 0x0 0x0 0x0 0x0 0x0 0x0 0x0 0x0 >;
			interrupt-parent = < &intc >;
			keyboard-controller;
			#gpio-cells = < 0x2 >;
		};
		pinctrl: pin-controller {
			compatible = "ite,it8xxx2-pinctrl";
			#address-cells = < 0x1 >;
			#size-cells = < 0x1 >;
			status = "okay";
		};
		pinctrla: pinctrl@f01660 {
			compatible = "ite,it8xxx2-pinctrl-func";
			reg = < 0xf01660 0x8 >;
			func3-gcr = < 0x0 0x0 0x0 0x0 0xf02032 0xf02032 0xf03e10 0xf03e10 >;
			func3-en-mask = < 0x0 0x0 0x0 0x0 0x2 0x2 0x10 0xc >;
			func4-gcr = < 0x0 0x0 0x0 0x0 0x0 0x0 0x0 0x0 >;
			func4-en-mask = < 0x0 0x0 0x0 0x0 0x0 0x0 0x0 0x0 >;
			volt-sel = < 0xf01648 0xf01648 0xf01648 0xf01648 0xf01648 0xf01648 0xf01648 0xf01648 >;
			volt-sel-mask = < 0x1 0x2 0x4 0x8 0x10 0x20 0x40 0x80 >;
			#pinmux-cells = < 0x2 >;
			gpio-group;
		};
		pinctrlb: pinctrl@f01668 {
			compatible = "ite,it8xxx2-pinctrl-func";
			reg = < 0xf01668 0x8 >;
			func3-gcr = < 0xf03e15 0xf03e15 0xf03e11 0x0 0x0 0xf03e11 0x0 0x0 >;
			func3-en-mask = < 0x1 0x2 0x20 0x0 0x0 0x20 0x0 0x0 >;
			func3-ext = < 0x0 0x0 0xf03e16 0x0 0x0 0xf03e16 0x0 0x0 >;
			func3-ext-mask = < 0x0 0x0 0x40 0x0 0x0 0x40 0x0 0x0 >;
			func4-gcr = < 0x0 0x0 0x0 0x0 0x0 0x0 0x0 0x0 >;
			func4-en-mask = < 0x0 0x0 0x0 0x0 0x0 0x0 0x0 0x0 >;
			volt-sel = < 0xf01649 0xf01649 0xf01649 0xf01649 0xf01649 0xf01649 0xf01649 0x0 >;
			volt-sel-mask = < 0x1 0x2 0x4 0x8 0x10 0x20 0x40 0x0 >;
			#pinmux-cells = < 0x2 >;
			gpio-group;
		};
		pinctrlc: pinctrl@f01670 {
			compatible = "ite,it8xxx2-pinctrl-func";
			reg = < 0xf01670 0x8 >;
			func3-gcr = < 0x0 0x0 0x0 0xf03e10 0x0 0xf03e10 0x0 0xf03e13 >;
			func3-en-mask = < 0x0 0x0 0x0 0x10 0x0 0x10 0x0 0x2 >;
			func4-gcr = < 0x0 0x0 0x0 0x0 0x0 0x0 0x0 0xf03e16 >;
			func4-en-mask = < 0x0 0x0 0x0 0x0 0x0 0x0 0x0 0x80 >;
			volt-sel = < 0xf0164a 0xf0164a 0xf0164a 0xf0164a 0xf0164a 0xf0164a 0xf0164a 0xf0164a >;
			volt-sel-mask = < 0x1 0x2 0x4 0x8 0x10 0x20 0x40 0x80 >;
			#pinmux-cells = < 0x2 >;
			gpio-group;
		};
		pinctrld: pinctrl@f01678 {
			compatible = "ite,it8xxx2-pinctrl-func";
			reg = < 0xf01678 0x8 >;
			func3-gcr = < 0x0 0x0 0x0 0x0 0x0 0xf03e10 0x0 0x0 >;
			func3-en-mask = < 0x0 0x0 0x0 0x0 0x0 0x2 0x0 0x0 >;
			func4-gcr = < 0xf03e16 0x0 0x0 0x0 0x0 0x0 0x0 0x0 >;
			func4-en-mask = < 0x80 0x0 0x0 0x0 0x0 0x0 0x0 0x0 >;
			volt-sel = < 0xf0164b 0xf0164b 0xf0164b 0xf0164b 0xf0164b 0xf0164b 0xf0164b 0xf0164b >;
			volt-sel-mask = < 0x1 0x2 0x4 0x8 0x10 0x20 0x40 0x80 >;
			#pinmux-cells = < 0x2 >;
			gpio-group;
		};
		pinctrle: pinctrl@f01680 {
			compatible = "ite,it8xxx2-pinctrl-func";
			reg = < 0xf01680 0x8 >;
			func3-gcr = < 0x0 0xf03e16 0xf03e16 0x0 0x0 0xf03e10 0x0 0x0 >;
			func3-en-mask = < 0x0 0x20 0x20 0x0 0x0 0x8 0x0 0x0 >;
			func3-ext = < 0xf02032 0xf02032 0xf02032 0x0 0x0 0x0 0x0 0xf02032 >;
			func3-ext-mask = < 0x1 0x2 0x2 0x0 0x0 0x0 0x0 0x1 >;
			func4-gcr = < 0xf03e13 0x0 0x0 0x0 0x0 0x0 0x0 0x0 >;
			func4-en-mask = < 0x1 0x0 0x0 0x0 0x0 0x0 0x0 0x0 >;
			volt-sel = < 0xf0164c 0xf0164c 0xf0164c 0xf0164c 0xf0164c 0xf0164c 0xf0164c 0xf0164c >;
			volt-sel-mask = < 0x1 0x2 0x4 0x8 0x10 0x20 0x40 0x80 >;
			#pinmux-cells = < 0x2 >;
			gpio-group;
		};
		pinctrlf: pinctrl@f01688 {
			compatible = "ite,it8xxx2-pinctrl-func";
			reg = < 0xf01688 0x8 >;
			func3-gcr = < 0xf03e15 0xf03e15 0xf03e10 0xf03e10 0x0 0x0 0xf03e11 0x0 >;
			func3-en-mask = < 0x4 0x8 0x2 0x2 0x0 0x0 0x10 0x0 >;
			func4-gcr = < 0x0 0x0 0x0 0x0 0x0 0x0 0x0 0x0 >;
			func4-en-mask = < 0x0 0x0 0x0 0x0 0x0 0x0 0x0 0x0 >;
			volt-sel = < 0xf0164d 0xf0164d 0xf0164d 0xf0164d 0xf0164d 0xf0164d 0xf0164d 0xf0164d >;
			volt-sel-mask = < 0x1 0x2 0x4 0x8 0x10 0x20 0x40 0x80 >;
			#pinmux-cells = < 0x2 >;
			gpio-group;
		};
		pinctrlg: pinctrl@f01690 {
			compatible = "ite,it8xxx2-pinctrl-func";
			reg = < 0xf01690 0x8 >;
			func3-gcr = < 0xf03e10 0xf03e10 0xf03e10 0x0 0x0 0x0 0xf03e10 0x0 >;
			func3-en-mask = < 0x20 0x8 0x10 0x0 0x0 0x0 0x2 0x0 >;
			func4-gcr = < 0x0 0x0 0x0 0x0 0x0 0x0 0x0 0x0 >;
			func4-en-mask = < 0x0 0x0 0x0 0x0 0x0 0x0 0x0 0x0 >;
			volt-sel = < 0xf0164e 0xf0164e 0xf0164e 0x0 0x0 0x0 0xf0164e 0x0 >;
			volt-sel-mask = < 0x1 0x2 0x4 0x0 0x0 0x0 0x40 0x0 >;
			#pinmux-cells = < 0x2 >;
			gpio-group;
		};
		pinctrlh: pinctrl@f01698 {
			compatible = "ite,it8xxx2-pinctrl-func";
			reg = < 0xf01698 0x8 >;
			func3-gcr = < 0x0 0xf03e11 0xf03e11 0x0 0x0 0x0 0x0 0x0 >;
			func3-en-mask = < 0x0 0x20 0x20 0x0 0x0 0x0 0x0 0x0 >;
			func4-gcr = < 0x0 0x0 0x0 0x0 0x0 0x0 0x0 0x0 >;
			func4-en-mask = < 0x0 0x0 0x0 0x0 0x0 0x0 0x0 0x0 >;
			volt-sel = < 0xf0164f 0xf0164f 0xf0164f 0xf0164f 0xf0164f 0xf0164f 0xf0164f 0x0 >;
			volt-sel-mask = < 0x1 0x2 0x4 0x8 0x10 0x20 0x40 0x0 >;
			#pinmux-cells = < 0x2 >;
			gpio-group;
		};
		pinctrli: pinctrl@f016a0 {
			compatible = "ite,it8xxx2-pinctrl-func";
			reg = < 0xf016a0 0x8 >;
			func3-gcr = < 0x0 0x0 0x0 0x0 0x0 0xf03e10 0xf03e10 0xf03e10 >;
			func3-en-mask = < 0x0 0x0 0x0 0x0 0x0 0x8 0x8 0x8 >;
			func4-gcr = < 0x0 0x0 0x0 0x0 0x0 0x0 0x0 0x0 >;
			func4-en-mask = < 0x0 0x0 0x0 0x0 0x0 0x0 0x0 0x0 >;
			volt-sel = < 0xf01650 0xf01650 0xf01650 0xf01650 0xf01650 0xf01650 0xf01650 0xf01650 >;
			volt-sel-mask = < 0x1 0x2 0x4 0x8 0x10 0x20 0x40 0x80 >;
			#pinmux-cells = < 0x2 >;
			gpio-group;
		};
		pinctrlj: pinctrl@f016a8 {
			compatible = "ite,it8xxx2-pinctrl-func";
			reg = < 0xf016a8 0x8 >;
			func3-gcr = < 0xf03e14 0x0 0xf03e14 0xf03e14 0xf03e10 0xf03e10 0x0 0x0 >;
			func3-en-mask = < 0x1 0x0 0x1 0x2 0x2 0x3 0x0 0x0 >;
			func4-gcr = < 0x0 0x0 0x0 0x0 0x0 0x0 0x0 0x0 >;
			func4-en-mask = < 0x0 0x0 0x0 0x0 0x0 0x0 0x0 0x0 >;
			volt-sel = < 0xf01651 0xf01651 0xf01651 0xf01651 0xf01651 0xf01651 0x0 0x0 >;
			volt-sel-mask = < 0x1 0x2 0x4 0x8 0x10 0x20 0x0 0x0 >;
			#pinmux-cells = < 0x2 >;
			gpio-group;
		};
		pinctrlk: pinctrl@f016b0 {
			compatible = "ite,it8xxx2-pinctrl-func";
			reg = < 0xf016b0 0x8 >;
			func3-gcr = < 0x0 0x0 0x0 0x0 0x0 0x0 0x0 0x0 >;
			func3-en-mask = < 0x0 0x0 0x0 0x0 0x0 0x0 0x0 0x0 >;
			func4-gcr = < 0x0 0x0 0x0 0x0 0x0 0x0 0x0 0x0 >;
			func4-en-mask = < 0x0 0x0 0x0 0x0 0x0 0x0 0x0 0x0 >;
			volt-sel = < 0xf01652 0xf01652 0xf01652 0xf01652 0xf01652 0xf01652 0xf01652 0xf01652 >;
			volt-sel-mask = < 0x1 0x2 0x4 0x8 0x10 0x20 0x40 0x80 >;
			#pinmux-cells = < 0x2 >;
			gpio-group;
		};
		pinctrll: pinctrl@f016b8 {
			compatible = "ite,it8xxx2-pinctrl-func";
			reg = < 0xf016b8 0x8 >;
			func3-gcr = < 0x0 0x0 0x0 0x0 0x0 0x0 0x0 0x0 >;
			func3-en-mask = < 0x0 0x0 0x0 0x0 0x0 0x0 0x0 0x0 >;
			func4-gcr = < 0x0 0x0 0x0 0x0 0x0 0x0 0x0 0x0 >;
			func4-en-mask = < 0x0 0x0 0x0 0x0 0x0 0x0 0x0 0x0 >;
			volt-sel = < 0xf01653 0xf01653 0xf01653 0xf01653 0xf01653 0xf01653 0xf01653 0xf01653 >;
			volt-sel-mask = < 0x1 0x2 0x4 0x8 0x10 0x20 0x40 0x80 >;
			#pinmux-cells = < 0x2 >;
			gpio-group;
		};
		pinctrlm: pinctrl@f016c0 {
			compatible = "ite,it8xxx2-pinctrl-func";
			reg = < 0xf016c0 0x8 >;
			func3-gcr = < 0x0 0x0 0x0 0x0 0x0 0x0 0x0 0x0 >;
			func3-en-mask = < 0x0 0x0 0x0 0x0 0x0 0x0 0x0 0x0 >;
			func4-gcr = < 0x0 0x0 0x0 0x0 0x0 0x0 0x0 0x0 >;
			func4-en-mask = < 0x0 0x0 0x0 0x0 0x0 0x0 0x0 0x0 >;
			volt-sel = < 0xf03e2d 0xf03e2d 0xf03e2d 0xf03e2d 0xf03e2d 0xf03e2d 0xf03e2d 0x0 >;
			volt-sel-mask = < 0x10 0x10 0x10 0x10 0x10 0x10 0x10 0x0 >;
			#pinmux-cells = < 0x2 >;
			gpio-group;
		};
		pinctrlksi: pinctrl@f01d40 {
			compatible = "ite,it8xxx2-pinctrl-func";
			reg = < 0xf01d40 0x8 0xf01d05 0x1 >;
			pp-od-mask = < 0x0 >;
			pullup-mask = < 0x4 >;
			#pinmux-cells = < 0x2 >;
		};
		pinctrlksol: pinctrl@f01d48 {
			compatible = "ite,it8xxx2-pinctrl-func";
			reg = < 0xf01d48 0x8 0xf01d02 0x1 >;
			pp-od-mask = < 0x1 >;
			pullup-mask = < 0x4 >;
			#pinmux-cells = < 0x2 >;
		};
		pinctrlksoh: pinctrl@f01d50 {
			compatible = "ite,it8xxx2-pinctrl-func";
			reg = < 0xf01d50 0x8 0xf01d02 0x1 >;
			pp-od-mask = < 0x1 >;
			pullup-mask = < 0x4 >;
			#pinmux-cells = < 0x2 >;
		};
		wuc1: wakeup-controller@f01b00 {
			compatible = "ite,it8xxx2-wuc";
			reg = < 0xf01b00 0x1 0xf01b01 0x1 0xf01b02 0x1 0xf01b03 0x1 >;
			wakeup-controller;
			#wuc-cells = < 0x1 >;
		};
		wuc2: wakeup-controller@f01b04 {
			compatible = "ite,it8xxx2-wuc";
			reg = < 0xf01b04 0x1 0xf01b05 0x1 0x0 0x1 0xf01b07 0x1 >;
			wakeup-controller;
			#wuc-cells = < 0x1 >;
			phandle = < 0x1 >;
		};
		wuc3: wakeup-controller@f01b08 {
			compatible = "ite,it8xxx2-wuc";
			reg = < 0xf01b08 0x1 0xf01b09 0x1 0xf01b0a 0x1 0xf01b0b 0x1 >;
			wakeup-controller;
			#wuc-cells = < 0x1 >;
			phandle = < 0x2 >;
		};
		wuc4: wakeup-controller@f01b0c {
			compatible = "ite,it8xxx2-wuc";
			reg = < 0xf01b0c 0x1 0xf01b0d 0x1 0xf01b0e 0x1 0xf01b0f 0x1 >;
			wakeup-controller;
			#wuc-cells = < 0x1 >;
			phandle = < 0x3 >;
		};
		wuc5: wakeup-controller@f01b10 {
			compatible = "ite,it8xxx2-wuc";
			reg = < 0xf01b10 0x1 0xf01b11 0x1 0x0 0x1 0xf01b13 0x1 >;
			wakeup-controller;
			#wuc-cells = < 0x1 >;
			phandle = < 0x4 >;
		};
		wuc6: wakeup-controller@f01b14 {
			compatible = "ite,it8xxx2-wuc";
			reg = < 0xf01b14 0x1 0xf01b15 0x1 0x0 0x1 0xf01b17 0x1 >;
			wakeup-controller;
			#wuc-cells = < 0x1 >;
			phandle = < 0x5 >;
		};
		wuc7: wakeup-controller@f01b18 {
			compatible = "ite,it8xxx2-wuc";
			reg = < 0xf01b18 0x1 0xf01b19 0x1 0x0 0x1 0xf01b1b 0x1 >;
			wakeup-controller;
			#wuc-cells = < 0x1 >;
			phandle = < 0x6 >;
		};
		wuc8: wakeup-controller@f01b1c {
			compatible = "ite,it8xxx2-wuc";
			reg = < 0xf01b1c 0x1 0xf01b1d 0x1 0x0 0x1 0xf01b1f 0x1 >;
			wakeup-controller;
			#wuc-cells = < 0x1 >;
			phandle = < 0x7 >;
		};
		wuc9: wakeup-controller@f01b20 {
			compatible = "ite,it8xxx2-wuc";
			reg = < 0xf01b20 0x1 0xf01b21 0x1 0x0 0x1 0xf01b23 0x1 >;
			wakeup-controller;
			#wuc-cells = < 0x1 >;
			phandle = < 0x8 >;
		};
		wuc10: wakeup-controller@f01b24 {
			compatible = "ite,it8xxx2-wuc";
			reg = < 0xf01b24 0x1 0xf01b25 0x1 0x0 0x1 0xf01b27 0x1 >;
			wakeup-controller;
			#wuc-cells = < 0x1 >;
			phandle = < 0x9 >;
		};
		wuc11: wakeup-controller@f01b28 {
			compatible = "ite,it8xxx2-wuc";
			reg = < 0xf01b28 0x1 0xf01b29 0x1 0x0 0x1 0xf01b2b 0x1 >;
			wakeup-controller;
			#wuc-cells = < 0x1 >;
			phandle = < 0xa >;
		};
		wuc12: wakeup-controller@f01b2c {
			compatible = "ite,it8xxx2-wuc";
			reg = < 0xf01b2c 0x1 0xf01b2d 0x1 0x0 0x1 0xf01b2f 0x1 >;
			wakeup-controller;
			#wuc-cells = < 0x1 >;
			phandle = < 0xb >;
		};
		wuc13: wakeup-controller@f01b30 {
			compatible = "ite,it8xxx2-wuc";
			reg = < 0xf01b30 0x1 0xf01b31 0x1 0x0 0x1 0xf01b33 0x1 >;
			wakeup-controller;
			#wuc-cells = < 0x1 >;
			phandle = < 0xc >;
		};
		wuc14: wakeup-controller@f01b34 {
			compatible = "ite,it8xxx2-wuc";
			reg = < 0xf01b34 0x1 0xf01b35 0x1 0x0 0x1 0xf01b37 0x1 >;
			wakeup-controller;
			#wuc-cells = < 0x1 >;
			phandle = < 0xd >;
		};
		wuc15: wakeup-controller@f01b38 {
			compatible = "ite,it8xxx2-wuc";
			reg = < 0xf01b38 0x1 0xf01b39 0x1 0x0 0x1 0xf01b3b 0x1 >;
			wakeup-controller;
			#wuc-cells = < 0x1 >;
			phandle = < 0xe >;
		};
		wuc16: wakeup-controller@f01b3c {
			compatible = "ite,it8xxx2-wuc";
			reg = < 0xf01b3c 0x1 0xf01b3d 0x1 0x0 0x1 0xf01b3f 0x1 >;
			wakeup-controller;
			#wuc-cells = < 0x1 >;
			phandle = < 0xf >;
		};
		i2c0: i2c@f04300 {
			compatible = "ite,enhance-i2c";
			#address-cells = < 0x1 >;
			#size-cells = < 0x0 >;
			reg = < 0xf04300 0x80 >;
			interrupts = < 0x9 0x4 >;
			interrupt-parent = < &intc >;
			status = "disabled";
			port-num = < 0x0 >;
			channel-switch-sel = < 0x0 >;
			scl-gpios = < &gpiob 0x3 0x0 >;
			sda-gpios = < &gpiob 0x4 0x0 >;
			clock-gate-offset = < 0x904 >;
		};
		i2c1: i2c@f04380 {
			compatible = "ite,enhance-i2c";
			#address-cells = < 0x1 >;
			#size-cells = < 0x0 >;
			reg = < 0xf04380 0x80 >;
			interrupts = < 0xa 0x4 >;
			interrupt-parent = < &intc >;
			status = "disabled";
			port-num = < 0x1 >;
			channel-switch-sel = < 0x1 >;
			scl-gpios = < &gpioc 0x1 0x0 >;
			sda-gpios = < &gpioc 0x2 0x0 >;
			clock-gate-offset = < 0x908 >;
		};
		i2c2: i2c@f04400 {
			compatible = "ite,enhance-i2c";
			#address-cells = < 0x1 >;
			#size-cells = < 0x0 >;
			reg = < 0xf04400 0x80 >;
			interrupts = < 0x10 0x4 >;
			interrupt-parent = < &intc >;
			status = "disabled";
			port-num = < 0x2 >;
			channel-switch-sel = < 0x2 >;
			scl-gpios = < &gpiof 0x6 0x0 >;
			sda-gpios = < &gpiof 0x7 0x0 >;
			clock-gate-offset = < 0x910 >;
		};
		i2c3: i2c@f04480 {
			compatible = "ite,enhance-i2c";
			#address-cells = < 0x1 >;
			#size-cells = < 0x0 >;
			reg = < 0xf04480 0x80 >;
			interrupts = < 0x4 0x4 >;
			interrupt-parent = < &intc >;
			status = "disabled";
			port-num = < 0x3 >;
			channel-switch-sel = < 0x3 >;
			scl-gpios = < &gpioh 0x1 0x0 >;
			sda-gpios = < &gpioh 0x2 0x0 >;
			clock-gate-offset = < 0x920 >;
		};
		i2c4: i2c@f04500 {
			compatible = "ite,enhance-i2c";
			#address-cells = < 0x1 >;
			#size-cells = < 0x0 >;
			reg = < 0xf04500 0x80 >;
			interrupts = < 0x98 0x4 >;
			interrupt-parent = < &intc >;
			status = "disabled";
			port-num = < 0x4 >;
			channel-switch-sel = < 0x4 >;
			scl-gpios = < &gpioe 0x0 0x0 >;
			sda-gpios = < &gpioe 0x7 0x0 >;
			clock-gate-offset = < 0x940 >;
		};
		i2c5: i2c@f04580 {
			compatible = "ite,enhance-i2c";
			#address-cells = < 0x1 >;
			#size-cells = < 0x0 >;
			reg = < 0xf04580 0x80 >;
			interrupts = < 0x99 0x4 >;
			interrupt-parent = < &intc >;
			status = "disabled";
			port-num = < 0x5 >;
			channel-switch-sel = < 0x5 >;
			scl-gpios = < &gpioa 0x4 0x0 >;
			sda-gpios = < &gpioa 0x5 0x0 >;
			clock-gate-offset = < 0x980 >;
		};
		usb0: usbd@f02f00 {
			compatible = "ite,it82xx2-usb";
			interrupts = < 0x17 0x4 0x57 0x4 >;
			interrupt-parent = < &intc >;
			wucctrl = < &wuc_wu90 >;
			reg = < 0xf02f00 0x100 >;
			status = "disabled";
			num-bidir-endpoints = < 0x1 >;
			num-in-endpoints = < 0xa >;
			num-out-endpoints = < 0x5 >;
		};
		sha0: crypto@f03c00 {
			compatible = "ite,it8xxx2-sha-v2";
			reg = < 0xf03c00 0x5 >;
			status = "disabled";
		};
	};
};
